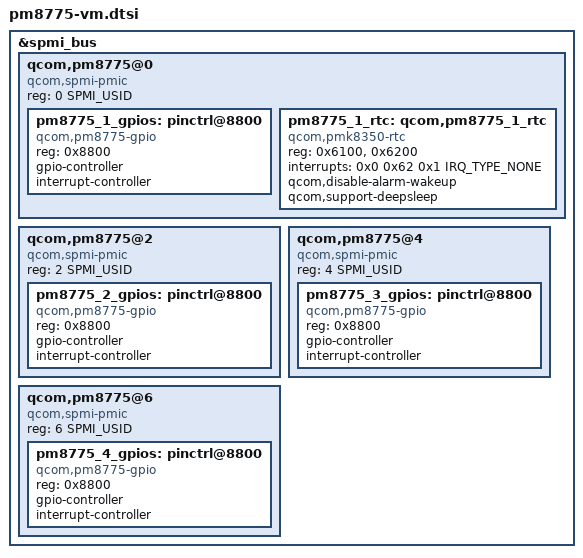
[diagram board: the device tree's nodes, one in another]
#include <dt-bindings/spmi/spmi.h>

&spmi_bus {

	qcom,pm8775@0 {
		compatible = "qcom,spmi-pmic";
		reg = <0 SPMI_USID>;
		#address-cells = <1>;
		#size-cells = <0>;

		pm8775_1_gpios: pinctrl@8800 {
			compatible = "qcom,pm8775-gpio";
			reg = <0x8800>;
			gpio-controller;
			#gpio-cells = <2>;
			interrupt-controller;
			#interrupt-cells = <2>;
		};

		pm8775_1_rtc: qcom,pm8775_1_rtc {
			compatible = "qcom,pmk8350-rtc";
			reg = <0x6100>, <0x6200>;
			reg-names = "rtc", "alarm";
			interrupts = <0x0 0x62 0x1 IRQ_TYPE_NONE>;
			qcom,disable-alarm-wakeup;
			qcom,support-deepsleep;
		};
	};

	qcom,pm8775@2 {
		compatible = "qcom,spmi-pmic";
		reg = <2 SPMI_USID>;
		#address-cells = <1>;
		#size-cells = <0>;

		pm8775_2_gpios: pinctrl@8800 {
			compatible = "qcom,pm8775-gpio";
			reg = <0x8800>;
			gpio-controller;
			#gpio-cells = <2>;
			interrupt-controller;
			#interrupt-cells = <2>;
		};
	};

	qcom,pm8775@4 {
		compatible = "qcom,spmi-pmic";
		reg = <4 SPMI_USID>;
		#address-cells = <1>;
		#size-cells = <0>;

		pm8775_3_gpios: pinctrl@8800 {
			compatible = "qcom,pm8775-gpio";
			reg = <0x8800>;
			gpio-controller;
			#gpio-cells = <2>;
			interrupt-controller;
			#interrupt-cells = <2>;
		};
	};

	qcom,pm8775@6 {
		compatible = "qcom,spmi-pmic";
		reg = <6 SPMI_USID>;
		#address-cells = <1>;
		#size-cells = <0>;

		pm8775_4_gpios: pinctrl@8800 {
			compatible = "qcom,pm8775-gpio";
			reg = <0x8800>;
			gpio-controller;
			#gpio-cells = <2>;
			interrupt-controller;
			#interrupt-cells = <2>;
		};
	};
};

